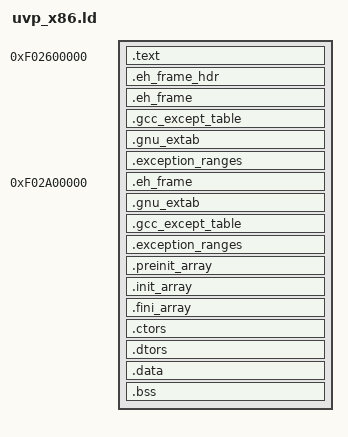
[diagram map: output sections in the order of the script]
OUTPUT_FORMAT(elf64-x86-64)
OUTPUT_ARCH(i386:x86-64)
ENTRY(start)

SECTIONS
{
    . = 0xf02400000;
    __openamp_phys_addr = .;
    __os_section_start = .;
    . = . + 0x40; /* reserved for mmu map link */
    __os_print_start = .;
    . = . + 0x100000;
    __os_print_end = .;

    . = 0xf02600000;
    .text : {
        *(.startup.text)
        *(.text)
        *(.text.*)
        __os_stub_text_start = .;
        *(.stub.text)
        __os_stub_text_end = .;
        *(.rodata)
        *(.rodata.*)
    }
    .eh_frame_hdr   : { *(.eh_frame_hdr) *(.eh_frame_entry .eh_frame_entry.*) }
    .eh_frame       : ONLY_IF_RO { KEEP (*(.eh_frame)) *(.eh_frame.*) }
    .gcc_except_table   : ONLY_IF_RO { *(.gcc_except_table .gcc_except_table.*) }
    .gnu_extab   : ONLY_IF_RO { *(.gnu_extab*) }
    /* These sections are generated by the Sun/Oracle C++ compiler.  */
    .exception_ranges   : ONLY_IF_RO { *(.exception_ranges*) }
    /* Adjust the address for the data segment.  We want to adjust up to
      the same address within the page on the next page up.  */

    . = 0xf02a00000;
    /* Exception handling  */
    .eh_frame       : ONLY_IF_RW { KEEP (*(.eh_frame)) *(.eh_frame.*) }
    .gnu_extab      : ONLY_IF_RW { *(.gnu_extab) }
    .gcc_except_table   : ONLY_IF_RW { *(.gcc_except_table .gcc_except_table.*) }
    .exception_ranges   : ONLY_IF_RW { *(.exception_ranges*) }
    .preinit_array    :
    {
        PROVIDE_HIDDEN (__preinit_array_start = .);
        KEEP (*(.preinit_array))
        PROVIDE_HIDDEN (__preinit_array_end = .);
    }
    .init_array    :
    {
        PROVIDE_HIDDEN (__init_array_start = .);
        KEEP (*(SORT_BY_INIT_PRIORITY(.init_array.*) SORT_BY_INIT_PRIORITY(.ctors.*)))
        KEEP (*(.init_array EXCLUDE_FILE (*crtbegin.o *crtbegin?.o *crtend.o *crtend?.o ) .ctors))
        PROVIDE_HIDDEN (__init_array_end = .);
    }
    .fini_array    :
    {
        PROVIDE_HIDDEN (__fini_array_start = .);
        KEEP (*(SORT_BY_INIT_PRIORITY(.fini_array.*) SORT_BY_INIT_PRIORITY(.dtors.*)))
        KEEP (*(.fini_array EXCLUDE_FILE (*crtbegin.o *crtbegin?.o *crtend.o *crtend?.o ) .dtors))
        PROVIDE_HIDDEN (__fini_array_end = .);
    }
    .ctors          :
    {
        KEEP (*(SORT(.ctors.*)))
        KEEP (*(.ctors))
    }
    .dtors          :
    {
        KEEP (*(SORT(.dtors.*)))
        KEEP (*(.dtors))
    }
    .data : {
        *(.data)
        *(.data.*)
        KEEP(*( SORT (.uniproton.table.*)));
        *(.tdata)
        __os_stub_data_start = .;
        *(.stub.data)
        __os_stub_data_end = .;
    }

    .bss : {
        __bss_start = .;
        *(*.bss)
        *(.bss.*)
        *(.tbss)
        __bss_end = .;
    }

    __os_sys_sp_start = .;
    . = . + 0x200000;
    __os_sys_sp_end = .;
    __os_section_end = .;
}
